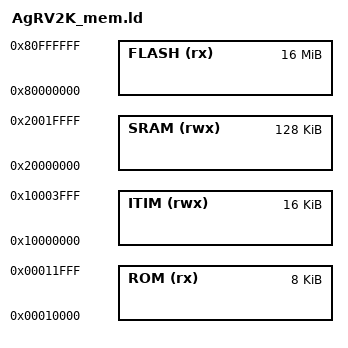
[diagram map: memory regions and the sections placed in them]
PROVIDE(FLASH_BASE = 0x80000000);
PROVIDE(FLASH_SIZE = 16M);
PROVIDE(OPTBY_BASE = 0x81000000);
PROVIDE(OPTBY_SIZE = 256);
PROVIDE(ITIM_BASE  = 0x10000000);
PROVIDE(ITIM_SIZE  = 16K);
PROVIDE(SRAM_BASE  = 0x20000000);
PROVIDE(SRAM_SIZE  = 128K);
PROVIDE(ROM_BASE   = 0x00010000);
PROVIDE(ROM_SIZE   = 8K);

MEMORY
{
  ROM   (rx)  : ORIGIN = ROM_BASE,   LENGTH = ROM_SIZE
  FLASH (rx)  : ORIGIN = FLASH_BASE, LENGTH = FLASH_SIZE
  SRAM  (rwx) : ORIGIN = SRAM_BASE,  LENGTH = SRAM_SIZE
  ITIM  (rwx) : ORIGIN = ITIM_BASE,  LENGTH = ITIM_SIZE
}
